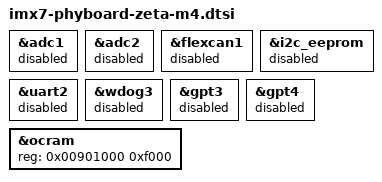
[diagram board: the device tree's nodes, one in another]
/*
 * Copyright (C) 2018 PHYTEC America, LLC
 *
 * This program is free software; you can redistribute it and/or modify
 * it under the terms of the GNU General Public License version 2 as
 * published by the Free Software Foundation.
 */

&adc1 {
	status = "disabled";
};

&adc2 {
	status = "disabled";
};

&flexcan1 {
	status = "disabled";
};

&i2c_eeprom {
	status = "disabled";
};

&uart2 {
	status = "disabled";
};

&wdog3 {
	status = "disabled";
};

&gpt3 {
	status = "disabled";
};

&gpt4 {
	status = "disabled";
};

&ocram {
	reg = <0x00901000 0xf000>;
};
